# haltium_cellcore register map
Vendor: Nordic Semiconductor; Series: nRFHaltium; File version: 1
CPU: CM33 r0p4, little endian, MPU, FPU, 3 interrupt priority bits, 480 interrupts
Registers are 32-bit, read-write, reset 0x0 unless marked. A register's access mark holds for its fields unless they carry their own. Offsets are from the block's base; [hi:lo] are bit positions; {n}, {i} and the like mark numbered series; 'fields as' and 'values as' point back to an identical list.

## LFCLKCALIBMEAS_NS — LFCLK calibration measurement 0
Base 0x44023000
Same registers: LFCLKCALIBMEAS_S 0x54023000
0x00 TASKS_START wo — Start Measuring
  [0] TASKS_START
    1=Trigger task
0x04 TASKS_STOP wo — Switch LfClkCalibMeas to STOPPED state. Brings LfClkCalibMeas from SHUTDOWN state to a configurable state before a measurement is launched.
  [0] TASKS_STOP
    1=Trigger task
0x08 TASKS_SHUTDOWN wo — Shut down LfClkCalibMeas
  [0] TASKS_SHUTDOWN
    1=Trigger task
0x100 EVENTS_COMPLETE — Measurement completed
  [0] EVENTS_COMPLETE
    0=NotGenerated (Event not generated); 1=Generated (Event generated)
0x300 INTEN — Enable or disable interrupt
  [0] COMPLETE — Enable or disable interrupt for event COMPLETE
    0=Disabled; 1=Enabled
0x304 INTENSET — Enable interrupt
  [0] COMPLETE — Write '1' to enable interrupt for event COMPLETE
    on read: 0=Disabled (Read: Disabled); 1=Enabled (Read: Enabled) | on write: 1=Set (Enable)
0x308 INTENCLR — Disable interrupt
  [0] COMPLETE — Write '1' to disable interrupt for event COMPLETE
    on read: 0=Disabled (Read: Disabled); 1=Enabled (Read: Enabled) | on write: 1=Clear (Disable)
0x30C INTPEND ro — Pending interrupts
  [0] COMPLETE — Read pending status of interrupt for event COMPLETE
    on read: 0=NotPending (Read: Not pending); 1=Pending (Read: Pending)
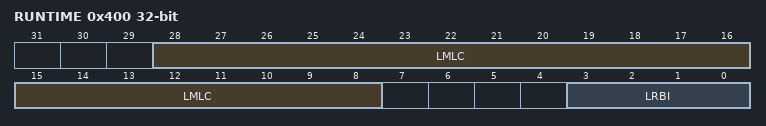
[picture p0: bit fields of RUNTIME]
0x400 RUNTIME ro — Runtime status of the measurement
  [28:8] LMLC — lastMeasuredLfCycle
  [3:0] LRBI — LastRingBufferIndex
0x404 LCMEAS0 ro — LfClk measurement result for the series0
  [31:0] LCMEAS
0x408 LCMEAS1 ro — LfClk measurement result for the series1
  [31:0] LCMEAS
{0x404+4i} LCMEAS{i} ro (i=2..4) — LfClk measurement results for the series{i}
  [31:0] LCMEAS
0x418 LCMEAS5 ro — LfClk measurement results for the series5
  [31:0] LCMEAS — LfClk measurement results for the series5. Only available, if HW parameter NUM_MEASUREMENTS set to larger than five.
0x41C LCMEAS6 ro — LfClk measurement results for the series6
  [31:0] LCMEAS — LfClk measurement results for the series6. Only available, if HW parameter NUM_MEASUREMENTS set to larger than six.
0x420 LCMEAS7 ro — LfClk measurement results for the series7
  [31:0] LCMEAS — LfClk measurement results for the series7. Only available, if HW parameter NUM_MEASUREMENTS set to larger than seven.
0x424 LCMEAS8 ro — LfClk measurement results for the series8
  [31:0] LCMEAS — LfClk measurement results for the series8. Only available, if HW parameter NUM_MEASUREMENTS set to larger than eight.
0x428 LCMEAS9 ro — LfClk measurement results for the series9
  [31:0] LCMEAS — LfClk measurement results for the series9. Only available, if HW parameter NUM_MEASUREMENTS set to larger than nine.
0x42C STATE ro — Current running state of the IP
  [1:0] STATE
    0=Shutdown (In SHUTDOWN state); 1=Stopped (In STOPPED state); 2=Running (In RUNNING state); 3=NotApplicable
0x500 MEASLEN — Length of the measurement
  [20:0] MEASLEN

## TIMEREVENTSYNCH_NS — Timer event synchronizer 0
Base 0x44024000
Same registers: TIMEREVENTSYNCH_S 0x54024000
0x00 CLOCKENABLE — Enable synchronizer clock
  [0] CLOCKENABLE — Enable
    0=Disable clock; 1=Enable clock

## TIMEMARKMUX0_NS — Timemark multiplexer for LTE System Timer 0
Base 0x44025000
Same registers: TIMEMARKMUX1_NS 0x44034000, TIMEMARKMUX0_S 0x54025000, TIMEMARKMUX1_S 0x54034000
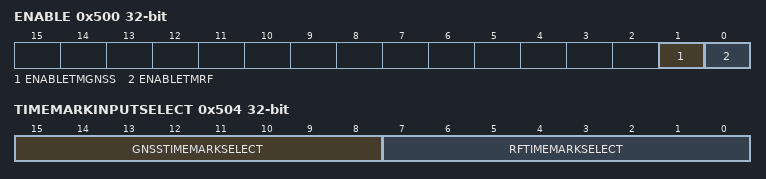
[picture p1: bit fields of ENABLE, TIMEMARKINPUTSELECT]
0x500 ENABLE — Enable Timemark Mux
  [1] ENABLETMGNSS — Enable
    0=Disable GNSS timemark output; 1=Enable GNSS timemark output
  [0] ENABLETMRF — Enable
    0=Disable RF timemark output; 1=Enable RF timemark output
0x504 TIMEMARKINPUTSELECT
  [15:8] GNSSTIMEMARKSELECT — GNSS timemark input select
    1=Event0 (Enable events[0] as timemark input); 2=Event1 (Enable events[1] as timemark input); 4=Event2 (Enable events[2] as timemark input); 8=Event3 (Enable events[3] as timemark input); 16=Event4 (Enable events[4] as timemark input); 32=Event5 (Enable events[5] as timemark input); 64=Event6 (Enable events[6] as timemark input); 128=Event7 (Enable events[7] as timemark input)
  [7:0] RFTIMEMARKSELECT — RF timemark input select
    values as GNSSTIMEMARKSELECT
